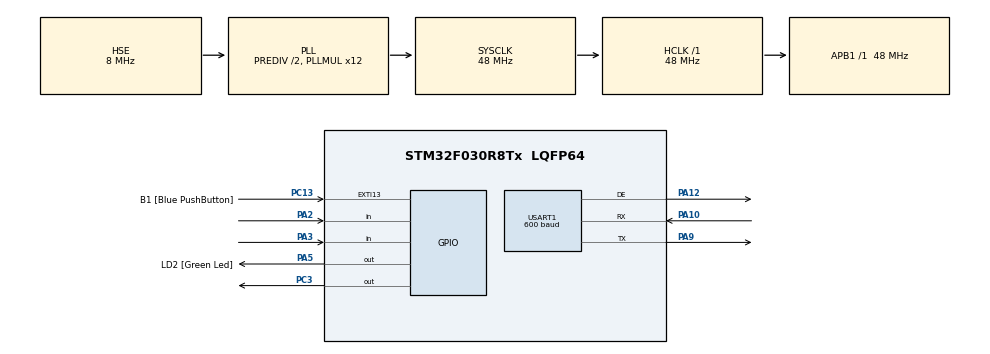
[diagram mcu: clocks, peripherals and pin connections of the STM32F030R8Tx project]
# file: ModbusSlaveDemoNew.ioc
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Dma.Request0=USART1_TX
Dma.USART1_TX.0.Direction=DMA_MEMORY_TO_PERIPH
Dma.USART1_TX.0.Instance=DMA1_Channel2
Dma.USART1_TX.0.MemDataAlignment=DMA_MDATAALIGN_BYTE
Dma.USART1_TX.0.MemInc=DMA_MINC_ENABLE
Dma.USART1_TX.0.Mode=DMA_NORMAL
Dma.USART1_TX.0.PeriphDataAlignment=DMA_PDATAALIGN_BYTE
Dma.USART1_TX.0.PeriphInc=DMA_PINC_DISABLE
Dma.USART1_TX.0.Priority=DMA_PRIORITY_LOW
FREERTOS.INCLUDE_vTaskDelayUntil=1
FREERTOS.Tasks01=defaultTask,0,128,StartDefaultTask,Default
Mcu.Family=STM32F0
Mcu.Name=STM32F030R8Tx
Mcu.Package=LQFP64
NVIC.DMA1_Channel2_3_IRQn=true\:3\:0\:false\:false\:true\:true
NVIC.EXTI4_15_IRQn=true\:3\:0\:false\:false\:true\:true
NVIC.TIM6_IRQn=true\:3\:0\:false\:false\:true\:true
NVIC.USART1_IRQn=true\:3\:0\:true\:false\:true\:true
PA10.Mode=Asynchronous
PA10.Signal=USART1_RX
PA12.Mode=Hardware Flow Control (RS485)
PA12.Signal=USART1_DE
PA13.GPIO_Label=TMS
PA13.Mode=Serial_Wire
PA13.Signal=SYS_SWDIO
PA14.GPIO_Label=TCK
PA14.Mode=Serial_Wire
PA14.Signal=SYS_SWCLK
PA2.Signal=GPIO_Input
PA3.Signal=GPIO_Input
PA5.GPIO_Label=LD2 [Green Led]
PA5.GPIO_Mode=GPIO_MODE_OUTPUT_PP
PA5.GPIO_PuPd=GPIO_NOPULL
PA5.GPIO_Speed=GPIO_SPEED_FREQ_LOW
PA5.Signal=GPIO_Output
PA9.Mode=Asynchronous
PA9.Signal=USART1_TX
PC13.GPIO_Label=B1 [Blue PushButton]
PC13.GPIO_ModeDefaultEXTI=GPIO_MODE_IT_RISING_FALLING
PC13.Signal=GPXTI13
PC14-OSC32_IN.Signal=RCC_OSC32_IN
PC15-OSC32_OUT.Signal=RCC_OSC32_OUT
PC3.GPIO_PuPd=GPIO_PULLDOWN
PC3.Signal=GPIO_Output
PF0-OSC_IN.Mode=HSE-External-Oscillator
PF0-OSC_IN.Signal=RCC_OSC_IN
PF1-OSC_OUT.Mode=HSE-External-Oscillator
PF1-OSC_OUT.Signal=RCC_OSC_OUT
ProjectManager.HeapSize=0x200
ProjectManager.StackSize=0x400
ProjectManager.TargetToolchain=SW4STM32
RCC.AHBFreq_Value=48000000
RCC.APB1Freq_Value=48000000
RCC.APB1TimFreq_Value=48000000
RCC.HCLKFreq_Value=48000000
RCC.PLLDivider=RCC_PREDIV_DIV2
RCC.PLLMUL=RCC_PLL_MUL12
RCC.PLLSourceVirtual=RCC_PLLSOURCE_HSE
RCC.SYSCLKFreq_VALUE=48000000
RCC.SYSCLKSource=RCC_SYSCLKSOURCE_PLLCLK
RCC.Usart1ClockSelection=RCC_USART1CLKSOURCE_HSI
TIM6.Period=0
TIM6.Prescaler=0
USART1.BaudRate=600
VP_FREERTOS_VS_ENABLE.Mode=Enabled
VP_TIM6_VS_ClockSourceINT.Mode=Enable_Timer
board=NUCLEO-F030R8

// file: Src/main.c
/**
  ******************************************************************************
  * File Name          : main.c
  * Description        : Main program body
  ******************************************************************************
  *
  * Copyright (c) 2017 STMicroelectronics International N.V.
  * All rights reserved.
  *
  * Redistribution and use in source and binary forms, with or without
  * modification, are permitted, provided that the following conditions are met:
  *
  * 1. Redistribution of source code must retain the above copyright notice,
  *    this list of conditions and the following disclaimer.
  * 2. Redistributions in binary form must reproduce the above copyright notice,
  *    this list of conditions and the following disclaimer in the documentation
  *    and/or other materials provided with the distribution.
  * 3. Neither the name of STMicroelectronics nor the names of other
  *    contributors to this software may be used to endorse or promote products
  *    derived from this software without specific written permission.
  * 4. This software, including modifications and/or derivative works of this
  *    software, must execute solely and exclusively on microcontroller or
  *    microprocessor devices manufactured by or for STMicroelectronics.
  * 5. Redistribution and use of this software other than as permitted under
  *    this license is void and will automatically terminate your rights under
  *    this license.
  *
  * THIS SOFTWARE IS PROVIDED BY STMICROELECTRONICS AND CONTRIBUTORS "AS IS"
  * AND ANY EXPRESS, IMPLIED OR STATUTORY WARRANTIES, INCLUDING, BUT NOT
  * LIMITED TO, THE IMPLIED WARRANTIES OF MERCHANTABILITY, FITNESS FOR A
  * PARTICULAR PURPOSE AND NON-INFRINGEMENT OF THIRD PARTY INTELLECTUAL PROPERTY
  * RIGHTS ARE DISCLAIMED TO THE FULLEST EXTENT PERMITTED BY LAW. IN NO EVENT
  * SHALL STMICROELECTRONICS OR CONTRIBUTORS BE LIABLE FOR ANY DIRECT, INDIRECT,
  * INCIDENTAL, SPECIAL, EXEMPLARY, OR CONSEQUENTIAL DAMAGES (INCLUDING, BUT NOT
  * LIMITED TO, PROCUREMENT OF SUBSTITUTE GOODS OR SERVICES; LOSS OF USE, DATA,
  * OR PROFITS; OR BUSINESS INTERRUPTION) HOWEVER CAUSED AND ON ANY THEORY OF
  * LIABILITY, WHETHER IN CONTRACT, STRICT LIABILITY, OR TORT (INCLUDING
  * NEGLIGENCE OR OTHERWISE) ARISING IN ANY WAY OUT OF THE USE OF THIS SOFTWARE,
  * EVEN IF ADVISED OF THE POSSIBILITY OF SUCH DAMAGE.
  *
  ******************************************************************************
  */
#include "main.h"
#include "stm32f0xx_hal.h"
#include "cmsis_os.h"
#include "dma.h"
#include "tim.h"
#include "usart.h"
#include "gpio.h"

/* USER CODE BEGIN Includes */

#include "u_modBusSlave.h"

/* USER CODE END Includes */

/* USER CODE BEGIN PV */
/* Private variables ---------------------------------------------------------*/

#define LD2_GPIO	GPIOA
#define LD2_PIN		GPIO_PIN_5

/* USER CODE END PV */

void SystemClock_Config(void);
void Error_Handler(void);
void MX_FREERTOS_Init(void);

/* USER CODE BEGIN PFP */
/* Private function prototypes -----------------------------------------------*/

mbsUart_t mbs;

/* USER CODE END PFP */

int main(void)
{

  /* MCU Configuration----------------------------------------------------------*/

  /* Reset of all peripherals, Initializes the Flash interface and the Systick. */
  HAL_Init();

  /* Configure the system clock */
  SystemClock_Config();

  /* Initialize all configured peripherals */
  MX_GPIO_Init();
  MX_DMA_Init();
  MX_USART1_UART_Init();
  MX_TIM6_Init();

  /* USER CODE BEGIN 2 */

  mbs.slaveAddr = 5;
  mbs.mbg.handle = &huart1;
  mbs.mbg.rxQ.toutTim = &htim6;
  mbs.mbg.rxQ.T35 = 3.5f;

  mbs_Init(&mbs, 1);

  /* USER CODE END 2 */

  /* Call init function for freertos objects (in freertos.c) */
  MX_FREERTOS_Init();

  /* Start scheduler */
  osKernelStart();

  /* We should never get here as control is now taken by the scheduler */

  /* Infinite loop */
  while (1)
  {

  }

}

/** System Clock Configuration
*/
void SystemClock_Config(void)
{

  RCC_OscInitTypeDef RCC_OscInitStruct;
  RCC_ClkInitTypeDef RCC_ClkInitStruct;
  RCC_PeriphCLKInitTypeDef PeriphClkInit;

    /**Initializes the CPU, AHB and APB busses clocks
    */
  RCC_OscInitStruct.OscillatorType = RCC_OSCILLATORTYPE_HSI|RCC_OSCILLATORTYPE_HSE;
  RCC_OscInitStruct.HSEState = RCC_HSE_ON;
  RCC_OscInitStruct.HSIState = RCC_HSI_ON;
  RCC_OscInitStruct.HSICalibrationValue = 16;
  RCC_OscInitStruct.PLL.PLLState = RCC_PLL_ON;
  RCC_OscInitStruct.PLL.PLLSource = RCC_PLLSOURCE_HSE;
  RCC_OscInitStruct.PLL.PLLMUL = RCC_PLL_MUL12;
  RCC_OscInitStruct.PLL.PREDIV = RCC_PREDIV_DIV2;
  if (HAL_RCC_OscConfig(&RCC_OscInitStruct) != HAL_OK)
  {
    Error_Handler();
  }

    /**Initializes the CPU, AHB and APB busses clocks
    */
  RCC_ClkInitStruct.ClockType = RCC_CLOCKTYPE_HCLK|RCC_CLOCKTYPE_SYSCLK
                              |RCC_CLOCKTYPE_PCLK1;
  RCC_ClkInitStruct.SYSCLKSource = RCC_SYSCLKSOURCE_PLLCLK;
  RCC_ClkInitStruct.AHBCLKDivider = RCC_SYSCLK_DIV1;
  RCC_ClkInitStruct.APB1CLKDivider = RCC_HCLK_DIV1;

  if (HAL_RCC_ClockConfig(&RCC_ClkInitStruct, FLASH_LATENCY_1) != HAL_OK)
  {
    Error_Handler();
  }

  PeriphClkInit.PeriphClockSelection = RCC_PERIPHCLK_USART1;
  PeriphClkInit.Usart1ClockSelection = RCC_USART1CLKSOURCE_HSI;
  if (HAL_RCCEx_PeriphCLKConfig(&PeriphClkInit) != HAL_OK)
  {
    Error_Handler();
  }

    /**Configure the Systick interrupt time
    */
  HAL_SYSTICK_Config(HAL_RCC_GetHCLKFreq()/1000);

    /**Configure the Systick
    */
  HAL_SYSTICK_CLKSourceConfig(SYSTICK_CLKSOURCE_HCLK);

  /* SysTick_IRQn interrupt configuration */
  HAL_NVIC_SetPriority(SysTick_IRQn, 3, 0);
}

void Error_Handler(void)
{
  /* USER CODE BEGIN Error_Handler */
  /* User can add his own implementation to report the HAL error return state */
  while(1)
  {
	  HAL_GPIO_WritePin(LD2_GPIO, LD2_PIN, 1);
  }
  /* USER CODE END Error_Handler */
}

#ifdef USE_FULL_ASSERT

/**
   * @brief Reports the name of the source file and the source line number
   * where the assert_param error has occurred.
   * @param file: pointer to the source file name
   * @param line: assert_param error line source number
   * @retval None
   */
void assert_failed(uint8_t* file, uint32_t line)
{
  /* USER CODE BEGIN 6 */

	// In this code all one can do is turn on a LED
	HAL_GPIO_WritePin(LD2_GPIO, LD2_PIN, 1);

  /* USER CODE END 6 */

}

#endif

/************************ (C) COPYRIGHT STMicroelectronics *****END OF FILE****/

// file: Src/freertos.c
/**
  ******************************************************************************
  * File Name          : freertos.c
  * Description        : Code for freertos applications
  ******************************************************************************
  *
  * Copyright (c) 2017 STMicroelectronics International N.V.
  * All rights reserved.
  *
  * Redistribution and use in source and binary forms, with or without
  * modification, are permitted, provided that the following conditions are met:
  *
  * 1. Redistribution of source code must retain the above copyright notice,
  *    this list of conditions and the following disclaimer.
  * 2. Redistributions in binary form must reproduce the above copyright notice,
  *    this list of conditions and the following disclaimer in the documentation
  *    and/or other materials provided with the distribution.
  * 3. Neither the name of STMicroelectronics nor the names of other
  *    contributors to this software may be used to endorse or promote products
  *    derived from this software without specific written permission.
  * 4. This software, including modifications and/or derivative works of this
  *    software, must execute solely and exclusively on microcontroller or
  *    microprocessor devices manufactured by or for STMicroelectronics.
  * 5. Redistribution and use of this software other than as permitted under
  *    this license is void and will automatically terminate your rights under
  *    this license.
  *
  * THIS SOFTWARE IS PROVIDED BY STMICROELECTRONICS AND CONTRIBUTORS "AS IS"
  * AND ANY EXPRESS, IMPLIED OR STATUTORY WARRANTIES, INCLUDING, BUT NOT
  * LIMITED TO, THE IMPLIED WARRANTIES OF MERCHANTABILITY, FITNESS FOR A
  * PARTICULAR PURPOSE AND NON-INFRINGEMENT OF THIRD PARTY INTELLECTUAL PROPERTY
  * RIGHTS ARE DISCLAIMED TO THE FULLEST EXTENT PERMITTED BY LAW. IN NO EVENT
  * SHALL STMICROELECTRONICS OR CONTRIBUTORS BE LIABLE FOR ANY DIRECT, INDIRECT,
  * INCIDENTAL, SPECIAL, EXEMPLARY, OR CONSEQUENTIAL DAMAGES (INCLUDING, BUT NOT
  * LIMITED TO, PROCUREMENT OF SUBSTITUTE GOODS OR SERVICES; LOSS OF USE, DATA,
  * OR PROFITS; OR BUSINESS INTERRUPTION) HOWEVER CAUSED AND ON ANY THEORY OF
  * LIABILITY, WHETHER IN CONTRACT, STRICT LIABILITY, OR TORT (INCLUDING
  * NEGLIGENCE OR OTHERWISE) ARISING IN ANY WAY OUT OF THE USE OF THIS SOFTWARE,
  * EVEN IF ADVISED OF THE POSSIBILITY OF SUCH DAMAGE.
  *
  ******************************************************************************
  */

#include "FreeRTOS.h"
#include "task.h"
#include "cmsis_os.h"

osThreadId defaultTaskHandle;

void StartDefaultTask(void const * argument);

void MX_FREERTOS_Init(void); /* (MISRA C 2004 rule 8.1) */

/* Hook prototypes */

/* Init FreeRTOS */

void MX_FREERTOS_Init(void) {

  /* Create the thread(s) */
  /* definition and creation of defaultTask */
  osThreadDef(defaultTask, StartDefaultTask, osPriorityNormal, 0, 128);
  defaultTaskHandle = osThreadCreate(osThread(defaultTask), NULL);

}

/* StartDefaultTask function */
void StartDefaultTask(void const * argument)
{

  /* USER CODE BEGIN StartDefaultTask */
  /* Infinite loop */
  for(;;)
  {
	  osThreadTerminate(0);
  }
  /* USER CODE END StartDefaultTask */
}

/************************ (C) COPYRIGHT STMicroelectronics *****END OF FILE****/
